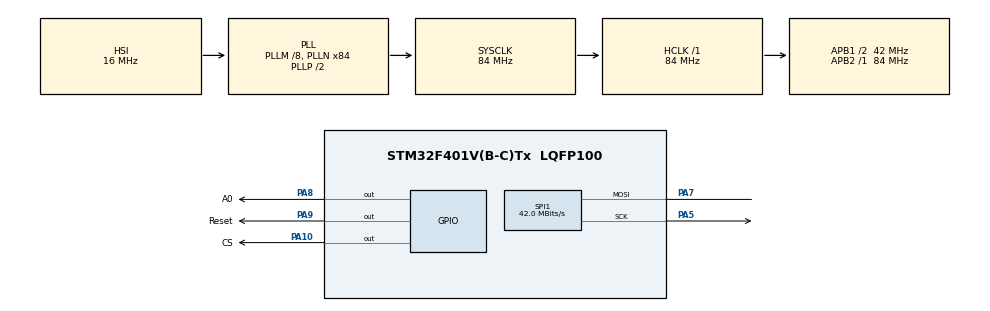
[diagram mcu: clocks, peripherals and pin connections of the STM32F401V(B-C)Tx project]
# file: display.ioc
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Mcu.Family=STM32F4
Mcu.Name=STM32F401V(B-C)Tx
Mcu.Package=LQFP100
NVIC.PriorityGroup=NVIC_PRIORITYGROUP_4
PA10.GPIO_Label=CS
PA10.GPIO_Speed=GPIO_SPEED_FREQ_HIGH
PA10.PinState=GPIO_PIN_RESET
PA10.Signal=GPIO_Output
PA13.Mode=Serial_Wire
PA13.Signal=SYS_JTMS-SWDIO
PA14.Mode=Serial_Wire
PA14.Signal=SYS_JTCK-SWCLK
PA5.Mode=Simplex_Bidirectional_Master
PA5.Signal=SPI1_SCK
PA7.Mode=Simplex_Bidirectional_Master
PA7.Signal=SPI1_MOSI
PA8.GPIO_Label=A0
PA8.GPIO_Speed=GPIO_SPEED_FREQ_HIGH
PA8.PinState=GPIO_PIN_RESET
PA8.Signal=GPIO_Output
PA9.GPIO_Label=Reset
PA9.GPIO_Speed=GPIO_SPEED_FREQ_HIGH
PA9.PinState=GPIO_PIN_RESET
PA9.Signal=GPIO_Output
PH0\ -\ OSC_IN.Mode=HSE-External-Oscillator
PH0\ -\ OSC_IN.Signal=RCC_OSC_IN
PH1\ -\ OSC_OUT.Mode=HSE-External-Oscillator
PH1\ -\ OSC_OUT.Signal=RCC_OSC_OUT
ProjectManager.HeapSize=0x400
ProjectManager.StackSize=0x800
ProjectManager.TargetToolchain=STM32CubeIDE
RCC.48MHZClocksFreq_Value=42000000
RCC.AHBFreq_Value=84000000
RCC.APB1CLKDivider=RCC_HCLK_DIV2
RCC.APB1Freq_Value=42000000
RCC.APB1TimFreq_Value=84000000
RCC.APB2Freq_Value=84000000
RCC.APB2TimFreq_Value=84000000
RCC.CortexFreq_Value=84000000
RCC.HCLKFreq_Value=84000000
RCC.HSE_VALUE=8000000
RCC.HSI_VALUE=16000000
RCC.LSE_VALUE=32768
RCC.PLLM=8
RCC.PLLN=84
RCC.SYSCLKFreq_VALUE=84000000
RCC.SYSCLKSource=RCC_SYSCLKSOURCE_PLLCLK
RCC.VCOOutputFreq_Value=168000000
SPI1.BaudRatePrescaler=SPI_BAUDRATEPRESCALER_2
SPI1.CalculateBaudRate=42.0 MBits/s
SPI1.Direction=SPI_DIRECTION_1LINE
SPI1.Mode=SPI_MODE_MASTER
SPI1.VirtualType=VM_MASTER
VP_FATFS_VS_Generic.Mode=User_defined
board=custom

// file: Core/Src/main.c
/* USER CODE BEGIN Header */
/**
  ******************************************************************************
  * @file           : main.c
  * @brief          : Main program body
  ******************************************************************************
  * @attention
  *
  * <h2><center>&copy; Copyright (c) 2021 STMicroelectronics.
  * All rights reserved.</center></h2>
  *
  * This software component is licensed by ST under BSD 3-Clause license,
  * the "License"; You may not use this file except in compliance with the
  * License. You may obtain a copy of the License at:
  *                        opensource.org/licenses/BSD-3-Clause
  *
  ******************************************************************************
  */
/* USER CODE END Header */
#include "main.h"
#include "fatfs.h"

SPI_HandleTypeDef hspi1;

void SystemClock_Config(void);
static void MX_GPIO_Init(void);
static void MX_SPI1_Init(void);

int main(void)
{

  /* MCU Configuration--------------------------------------------------------*/

  /* Reset of all peripherals, Initializes the Flash interface and the Systick. */
  HAL_Init();

  /* Configure the system clock */
  SystemClock_Config();

  /* Initialize all configured peripherals */
  MX_GPIO_Init();
  MX_SPI1_Init();
  MX_FATFS_Init();
  /* USER CODE BEGIN 2 */
  USARTinit();
  ST7735_Init();

  ST7735_FillScreen(ST7735_RED);
  SPI2_Init();

  /* USER CODE END 2 */

  /* Infinite loop */
  while (1)
  {
	  //uint8_t SDCardResult = SD_CheckCard();
	  //SPI2_SendByte(SDCardResult);
	  //char SDBuffer[2];
	  //itoa(SDCardResult, SDBuffer, 10);
    /* USER CODE BEGIN 3 */
	   // ST7735_DrawString(10, 30, SDBuffer, Font_11x18, ST7735_RED, ST7735_BLACK);
	  ST7735_DrawString(10, 0, "hello2", Font_11x18, ST7735_RED, ST7735_BLACK);

	  if (buffer_index > 0) {
	 	      ST7735_FillScreen(ST7735_BLUE);

	       // Вызываем функцию для вывода текста на дисплей
	       ST7735_DrawString(10, 0, buffer, Font_11x18, ST7735_RED, ST7735_BLACK);
	       // Очищаем буфер
	       buffer_index = 0;
	       buffer[0] = '\0';
	 	  }

  }
  /* USER CODE END 3 */
}

void SystemClock_Config(void)
{
  RCC_OscInitTypeDef RCC_OscInitStruct = {0};
  RCC_ClkInitTypeDef RCC_ClkInitStruct = {0};

  /** Configure the main internal regulator output voltage
  */
  __HAL_RCC_PWR_CLK_ENABLE();
  __HAL_PWR_VOLTAGESCALING_CONFIG(PWR_REGULATOR_VOLTAGE_SCALE2);
  /** Initializes the RCC Oscillators according to the specified parameters
  * in the RCC_OscInitTypeDef structure.
  */
  RCC_OscInitStruct.OscillatorType = RCC_OSCILLATORTYPE_HSI;
  RCC_OscInitStruct.HSIState = RCC_HSI_ON;
  RCC_OscInitStruct.HSICalibrationValue = RCC_HSICALIBRATION_DEFAULT;
  RCC_OscInitStruct.PLL.PLLState = RCC_PLL_ON;
  RCC_OscInitStruct.PLL.PLLSource = RCC_PLLSOURCE_HSI;
  RCC_OscInitStruct.PLL.PLLM = 8;
  RCC_OscInitStruct.PLL.PLLN = 84;
  RCC_OscInitStruct.PLL.PLLP = RCC_PLLP_DIV2;
  RCC_OscInitStruct.PLL.PLLQ = 4;
  if (HAL_RCC_OscConfig(&RCC_OscInitStruct) != HAL_OK)
  {
    Error_Handler();
  }
  /** Initializes the CPU, AHB and APB buses clocks
  */
  RCC_ClkInitStruct.ClockType = RCC_CLOCKTYPE_HCLK|RCC_CLOCKTYPE_SYSCLK
                              |RCC_CLOCKTYPE_PCLK1|RCC_CLOCKTYPE_PCLK2;
  RCC_ClkInitStruct.SYSCLKSource = RCC_SYSCLKSOURCE_PLLCLK;
  RCC_ClkInitStruct.AHBCLKDivider = RCC_SYSCLK_DIV1;
  RCC_ClkInitStruct.APB1CLKDivider = RCC_HCLK_DIV2;
  RCC_ClkInitStruct.APB2CLKDivider = RCC_HCLK_DIV1;

  if (HAL_RCC_ClockConfig(&RCC_ClkInitStruct, FLASH_LATENCY_2) != HAL_OK)
  {
    Error_Handler();
  }
}

static void MX_SPI1_Init(void)
{

  /* SPI1 parameter configuration*/
  hspi1.Instance = SPI1;
  hspi1.Init.Mode = SPI_MODE_MASTER;
  hspi1.Init.Direction = SPI_DIRECTION_1LINE;
  hspi1.Init.DataSize = SPI_DATASIZE_8BIT;
  hspi1.Init.CLKPolarity = SPI_POLARITY_LOW;
  hspi1.Init.CLKPhase = SPI_PHASE_1EDGE;
  hspi1.Init.NSS = SPI_NSS_SOFT;
  hspi1.Init.BaudRatePrescaler = SPI_BAUDRATEPRESCALER_2;
  hspi1.Init.FirstBit = SPI_FIRSTBIT_MSB;
  hspi1.Init.TIMode = SPI_TIMODE_DISABLE;
  hspi1.Init.CRCCalculation = SPI_CRCCALCULATION_DISABLE;
  hspi1.Init.CRCPolynomial = 10;
  if (HAL_SPI_Init(&hspi1) != HAL_OK)
  {
    Error_Handler();
  }

}

static void MX_GPIO_Init(void)
{
  GPIO_InitTypeDef GPIO_InitStruct = {0};

  /* GPIO Ports Clock Enable */
  __HAL_RCC_GPIOH_CLK_ENABLE();
  __HAL_RCC_GPIOA_CLK_ENABLE();

  /*Configure GPIO pin Output Level */
  HAL_GPIO_WritePin(GPIOA, A0_Pin|Reset_Pin|CS_Pin, GPIO_PIN_RESET);

  /*Configure GPIO pins : A0_Pin Reset_Pin CS_Pin */
  GPIO_InitStruct.Pin = A0_Pin|Reset_Pin|CS_Pin;
  GPIO_InitStruct.Mode = GPIO_MODE_OUTPUT_PP;
  GPIO_InitStruct.Pull = GPIO_NOPULL;
  GPIO_InitStruct.Speed = GPIO_SPEED_FREQ_HIGH;
  HAL_GPIO_Init(GPIOA, &GPIO_InitStruct);

}

void Error_Handler(void)
{
  __disable_irq();
  while (1)
  {
  }
}

/************************ (C) COPYRIGHT STMicroelectronics *****END OF FILE****/
